# Montana register map
Vendor: ONSemiconductor; Series: Montana Series; File version: 1.0
CPU: CM33 r0p4, little endian, MPU, FPU, 3 interrupt priority bits
Registers are 32-bit, read-write, reset 0x0 unless marked. A register's access mark holds for its fields unless they carry their own. Offsets are from the block's base; [hi:lo] are bit positions.

## TOF — Time Of Flight Timer
Base 0x40001B00
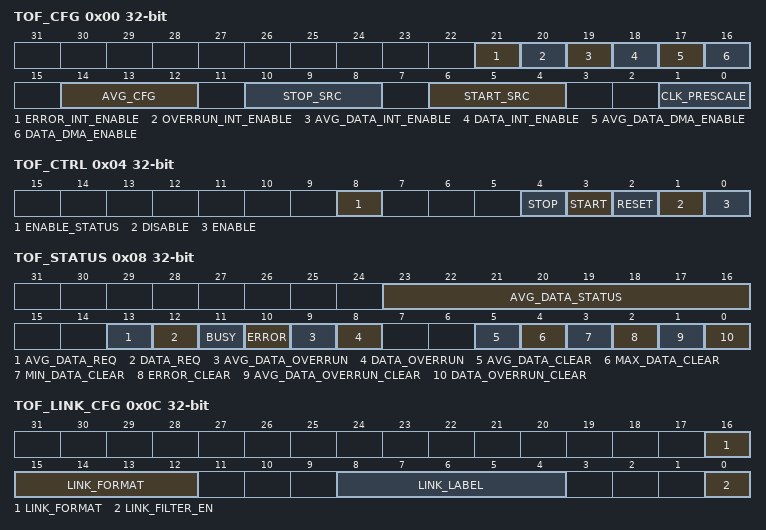
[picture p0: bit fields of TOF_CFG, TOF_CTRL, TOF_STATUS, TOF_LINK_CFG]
0x00 TOF_CFG — Time Of Flight Timer Configuration
  [21] ERROR_INT_ENABLE — Enable the interrupt generation when an error is detected
    0=TOF_ERROR_INT_DISABLE (Disable the error interrupt generation); 1=TOF_ERROR_INT_ENABLE (Enable the error interrupt generation)
  [20] OVERRUN_INT_ENABLE — Enable the interrupt generation when a data or average data overrun is detected
    0=TOF_OVERRUN_INT_DISABLE (Disable the overrun interrupt generation); 1=TOF_OVERRUN_INT_ENABLE (Enable the overrun interrupt generation)
  [19] AVG_DATA_INT_ENABLE — Enable the interrupt generation when a new average data is available
    0=TOF_AVG_DATA_INT_DISABLE (Disable the average data interrupt generation); 1=TOF_AVG_DATA_INT_ENABLE (Enable the average data interrupt generation)
  [18] DATA_INT_ENABLE — Enable the interrupt generation when a new data is available
    0=TOF_DATA_INT_DISABLE (Disable the data interrupt generation); 1=TOF_DATA_INT_ENABLE (Enable the data interrupt generation)
  [17] AVG_DATA_DMA_ENABLE — Enable the DMA request when a new average data is available
    0=TOF_AVG_DATA_DMA_DISABLE (Disable the average data DMA request); 1=TOF_AVG_DATA_DMA_ENABLE (Enable the average data DMA request)
  [16] DATA_DMA_ENABLE — Enable the DMA request when a new data is available
    0=TOF_DATA_DMA_DISABLE (Disable the data DMA request); 1=TOF_DATA_DMA_ENABLE (Enable the data DMA request)
  [14:12] AVG_CFG — Select the amount of data for averaging
    0=TOF_AVG_DATA_1 (Store the latest data until the next stop trigger occurs); 1=TOF_AVG_DATA_2 (Compute average of 2 consecutive data); 2=TOF_AVG_DATA_4 (Compute average of 4 consecutive data); 3=TOF_AVG_DATA_8 (Compute average of 8 consecutive data); 4=TOF_AVG_DATA_16 (Compute average of 16 consecutive data); 5=TOF_AVG_DATA_32 (Compute average of 32 consecutive data); 6=TOF_AVG_DATA_64 (Compute average of 64 consecutive data); 7=TOF_AVG_DATA_128 (Compute average of 128 consecutive data)
  [10:8] STOP_SRC — Select the source of the external stop trigger
    0=TOF_STOP_SRC_NONE (Disable external stop trigger); 1=TOF_STOP_SRC_TX (Select TX radio interrupt to stop the time of flight timer); 2=TOF_STOP_SRC_RX_STOP (Select RX_STOP radio interrupt to stop the time of flight timer); 3=TOF_STOP_SRC_RX_RECEIVED (Select RX_RECEIVE radio interrupt to stop the time of flight timer); 4=TOF_STOP_SRC_SYNC (Select SYNC radio interrupt to stop the time of flight timer); 5=TOF_STOP_SRC_TX_FIFO (Select TX_FIFO radio interrupt to stop the time of flight timer); 6=TOF_STOP_SRC_RX_FIFO (Select RX_FIFO radio interrupt to stop the time of flight timer)
  [6:4] START_SRC — Select the source of the external start trigger
    0=TOF_START_SRC_NONE (Disable external start trigger); 1=TOF_START_SRC_TX (Select TX radio interrupt to start the time of flight timer); 2=TOF_START_SRC_RX_STOP (Select RX_STOP radio interrupt to start the time of flight timer); 3=TOF_START_SRC_RX_RECEIVED (Select RX_RECEIVE radio interrupt to start the time of flight timer); 4=TOF_START_SRC_SYNC (Select SYNC radio interrupt to start the time of flight timer); 5=TOF_START_SRC_TX_FIFO (Select TX_FIFO radio interrupt to start the time of flight timer); 6=TOF_START_SRC_RX_FIFO (Select RX_FIFO radio interrupt to start the time of flight timer)
  [1:0] CLK_PRESCALE — Select the time of flight timer clock prescale
    0=TOF_CLK_PRESCALE_1 (Divide the system clock by 1 (SYSCLK @ 8 MHz)); 1=TOF_CLK_PRESCALE_2 (Divide the system clock by 2 (SYSCLK @ 16 MHz)); 2=TOF_CLK_PRESCALE_3 (Divide the system clock by 3 (SYSCLK @ 24 MHz)); 3=TOF_CLK_PRESCALE_6 (Divide the system clock by 6 (SYSCLK @ 48 MHz))
0x04 TOF_CTRL (reset mask 0x100) — Time Of Flight Timer Control
  [8] ENABLE_STATUS ro — Status of the time of flight timer
    0=TOF_STATUS_DISABLED (Time of flight timer is disabled); 1=TOF_STATUS_ENABLED (Time of flight timer is enabled)
  [4] STOP wo — Stop the time of flight timer
    1=TOF_STOP (Stop the time of flight timer)
  [3] START wo — Start the time of flight timer
    1=TOF_START (Start the time of flight timer)
  [2] RESET wo — Synchronously reset the time of flight timer
    1=TOF_RESET (Synchronously reset the time of flight timer)
  [1] DISABLE wo — Disable the time of flight timer
    1=TOF_DISABLE (Disable the time of flight timer)
  [0] ENABLE wo — Enable the time of flight timer
    1=TOF_ENABLE (Enable the time of flight timer)
0x08 TOF_STATUS (reset mask 0xFF3F00) — Time Of Flight Timer Status
  [23:16] AVG_DATA_STATUS ro — Average data timer status
    0=TOF_AVG_DATA_STATUS (Remaining data for averaging)
  [13] AVG_DATA_REQ ro — Indicate that a new average data can be read
    0=TOF_NO_AVG_DATA_REQ (New average data are not yet available); 1=TOF_AVG_DATA_REQ (New average data can be read)
  [12] DATA_REQ ro — Indicate that a new data can be read
    0=TOF_NO_DATA_REQ (New data are not yet available); 1=TOF_DATA_REQ (New data can be read)
  [11] BUSY ro — Indicate if the time of flight timer is idle or busy
    0=TOF_IDLE (The time of flight timer is idle); 1=TOF_BUSY (The time of flight timer is busy)
  [10] ERROR ro — Detect two consecutive start triggers (sticky bit)
    0=TOF_NO_ERROR (Start and stop triggers occurred); 1=TOF_ERROR (Two consecutive start triggers occurred)
  [9] AVG_DATA_OVERRUN ro — Indicate that an average data overrun has occurred (sticky bit)
    0=TOF_NO_AVG_DATA_OVERRUN (No average data overrun detected); 1=TOF_AVG_DATA_OVERRUN (Data average overrun detected)
  [8] DATA_OVERRUN ro — Indicate that a data overrun has occurred (sticky bit)
    0=TOF_NO_DATA_OVERRUN (No data overrun detected); 1=TOF_DATA_OVERRUN (Data overrun detected)
  [5] AVG_DATA_CLEAR wo — Clear the average data register and restart the average computation
    1=TOF_AVG_DATA_CLEAR (Clear the average data register and restart the average computation)
  [4] MAX_DATA_CLEAR wo — Clear the max data register
    1=TOF_MAX_DATA_CLEAR (Clear the max data register)
  [3] MIN_DATA_CLEAR wo — Clear the min data register
    1=TOF_MIN_DATA_CLEAR (Clear the min data register)
  [2] ERROR_CLEAR wo — Clear the error flag
    1=TOF_ERROR_CLEAR (Clear the error flag)
  [1] AVG_DATA_OVERRUN_CLEAR wo — Clear the average data overrun flag
    1=TOF_AVG_DATA_OVERRUN_CLEAR (Clear the average data overrun flag)
  [0] DATA_OVERRUN_CLEAR wo — Clear the data overrun flag
    1=TOF_DATA_OVERRUN_CLEAR (Clear the data overrun flag)
0x0C TOF_LINK_CFG — Time Of Flight Timer BLE Link Filtering Configuration
  [16:12] LINK_FORMAT — Configure the link format for BLE link filtering
    0=TOF_LINK_FORMAT (Format of the BLE link to filter in the radio interrupts)
  [8:4] LINK_LABEL — Configure the link label for BLE link filtering
    0=TOF_LINK_LABEL (Label of the BLE link to filter in the radio interrupts)
  [0] LINK_FILTER_EN — Enable the BLE link filtering based on link label and format
    0=TOF_LINK_FILTER_DISABLE (Disable external start trigger); 1=TOF_LINK_FILTER_ENABLE (Select TX radio interrupt to start the Time of flight timer)
0x10 TOF_DATA ro — Time Of Flight Timer Data
  [19:0] DATA — Time of flight timer data (unsigned)
0x14 TOF_MIN_DATA ro reset 0xFFFFF — Time Of Flight Timer Minimum Data
  [19:0] MIN_DATA — Time of flight minimum data (unsigned)
0x18 TOF_MAX_DATA ro — Time Of Flight Timer Maximum Data
  [19:0] MAX_DATA — Time of flight maximum data (unsigned)
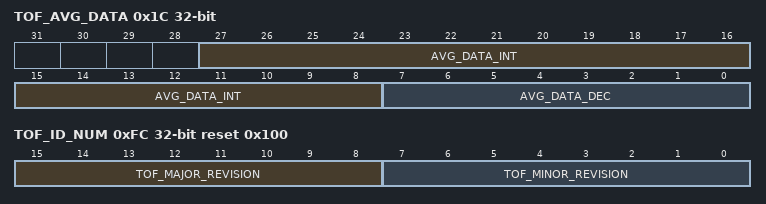
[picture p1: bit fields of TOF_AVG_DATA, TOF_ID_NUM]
0x1C TOF_AVG_DATA ro — Time Of Flight Timer Average Data
  [27:8] AVG_DATA_INT — Time of flight average data (unsigned integer part)
  [7:0] AVG_DATA_DEC — Time of flight average data (unsigned decimal part)
0xFC TOF_ID_NUM ro reset 0x100 — Time Of Flight Timer ID Number
  [15:8] TOF_MAJOR_REVISION — Time of flight timer major revision number
    1=TOF_MAJOR_REVISION (TOF revision 1.0)
  [7:0] TOF_MINOR_REVISION — Time of flight timer minor revision number
    0=TOF_MINOR_REVISION (TOF revision 1.0)
